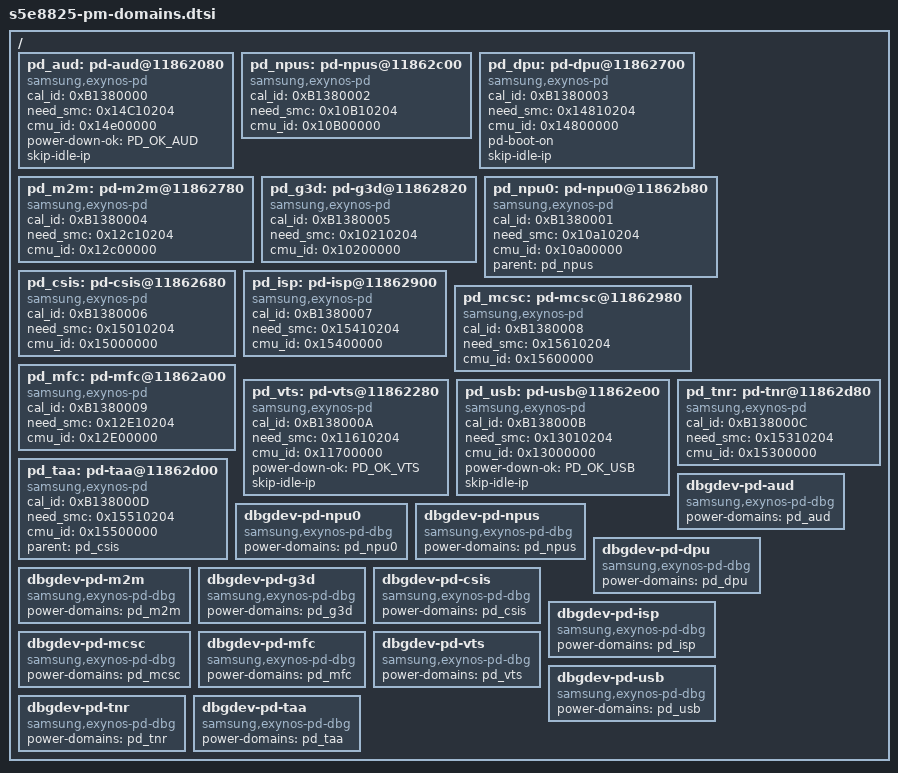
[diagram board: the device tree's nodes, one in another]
/*
 * SAMSUNG EXYNOS2100 SoC PM Domains device tree source
 *
 * Copyright (c) 2019 Samsung Electronics Co., Ltd.
 *		http://www.samsung.com
 *
 * SAMSUNG S5E8825 SoC PM domains device nodes are listed in this file.
 * EXYNOS9830 based board files can include this file and provide
 * values for board specfic bindings.
 *
 * This program is free software; you can redistribute it and/or modify
 * it under the terms of the GNU General Public License version 2 as
 * published by the Free Software Foundation.
 */
#include <dt-bindings/power/exynos-power.h>

/ {
	pd_aud: pd-aud@11862080 {
		compatible = "samsung,exynos-pd";
		cal_id = <0xB1380000>;
		need_smc = <0x14C10204>;
		cmu_id = <0x14e00000>;
		status = "okay";
		power-down-ok = <PD_OK_AUD>;
		#power-domain-cells = <0>;
		skip-idle-ip;
	};

	pd_npus: pd-npus@11862c00 {
		compatible = "samsung,exynos-pd";
		cal_id = <0xB1380002>;
		need_smc = <0x10B10204>;
		cmu_id = <0x10B00000>;
		status = "okay";
		#power-domain-cells = <0>;
	};

	pd_dpu: pd-dpu@11862700 {
		compatible = "samsung,exynos-pd";
		cal_id = <0xB1380003>;
		need_smc = <0x14810204>;
		cmu_id = <0x14800000>;
		status = "okay";
		#power-domain-cells = <0>;
		pd-boot-on;
		skip-idle-ip;
	};

	pd_m2m: pd-m2m@11862780 {
		compatible = "samsung,exynos-pd";
		cal_id = <0xB1380004>;
		need_smc = <0x12c10204>;
		cmu_id = <0x12c00000>;
		status = "okay";
		#power-domain-cells = <0>;
	};

	pd_g3d: pd-g3d@11862820 {
		compatible = "samsung,exynos-pd";
		cal_id = <0xB1380005>;
		need_smc = <0x10210204>;
		cmu_id = <0x10200000>;
		status = "okay";
		#power-domain-cells = <0>;
	};

	pd_npu0: pd-npu0@11862b80 {
		compatible = "samsung,exynos-pd";
		cal_id = <0xB1380001>;
		need_smc = <0x10a10204>;
		cmu_id = <0x10a00000>;
		status = "okay";
		parent = <&pd_npus>;
		#power-domain-cells = <0>;
	};

	pd_csis: pd-csis@11862680 {
		compatible = "samsung,exynos-pd";
		cal_id = <0xB1380006>;
		need_smc = <0x15010204>;
		cmu_id = <0x15000000>;
		status = "okay";
		#power-domain-cells = <0>;
	};

	pd_isp: pd-isp@11862900 {
		compatible = "samsung,exynos-pd";
		cal_id = <0xB1380007>;
		need_smc = <0x15410204>;
		cmu_id = <0x15400000>;
		status = "okay";
		#power-domain-cells = <0>;
	};

	pd_mcsc: pd-mcsc@11862980 {
		compatible = "samsung,exynos-pd";
		cal_id = <0xB1380008>;
		need_smc = <0x15610204>;
		cmu_id = <0x15600000>;
		status = "okay";
		#power-domain-cells = <0>;
	};

	pd_mfc: pd-mfc@11862a00 {
		compatible = "samsung,exynos-pd";
		cal_id = <0xB1380009>;
		need_smc = < 0x12E10204>;
		cmu_id = <0x12E00000>;
		status = "okay";
		#power-domain-cells = <0>;
	};

	pd_vts: pd-vts@11862280 {
		compatible = "samsung,exynos-pd";
		cal_id = <0xB138000A>;
		need_smc = <0x11610204>;
		cmu_id = <0x11700000>;
		status = "okay";
		power-down-ok = <PD_OK_VTS>;
		#power-domain-cells = <0>;
		skip-idle-ip;
	};

	pd_usb: pd-usb@11862e00 {
		compatible = "samsung,exynos-pd";
		cal_id = <0xB138000B>;
		need_smc = <0x13010204>;
		cmu_id = <0x13000000>;
		status = "okay";
		#power-domain-cells = <0>;
		power-down-ok = <PD_OK_USB>;
		skip-idle-ip;
	};

	pd_tnr: pd-tnr@11862d80 {
		compatible = "samsung,exynos-pd";
		cal_id = <0xB138000C>;
		need_smc = <0x15310204>;
		cmu_id = <0x15300000>;
		status = "okay";
		#power-domain-cells = <0>;
	};

	pd_taa: pd-taa@11862d00 {
		compatible = "samsung,exynos-pd";
		cal_id = <0xB138000D>;
		need_smc = <0x15510204>;
		cmu_id = <0x15500000>;
		status = "okay";
		parent = <&pd_csis>;
		#power-domain-cells = <0>;
	};

	dbgdev-pd-aud {
		compatible = "samsung,exynos-pd-dbg";
		power-domains = <&pd_aud>;
	};

	dbgdev-pd-npu0 {
		compatible = "samsung,exynos-pd-dbg";
		power-domains = <&pd_npu0>;
	};

	dbgdev-pd-npus {
		compatible = "samsung,exynos-pd-dbg";
		power-domains = <&pd_npus>;
	};

	dbgdev-pd-dpu {
		compatible = "samsung,exynos-pd-dbg";
		power-domains = <&pd_dpu>;
	};

	dbgdev-pd-m2m {
		compatible = "samsung,exynos-pd-dbg";
		power-domains = <&pd_m2m>;
	};

	dbgdev-pd-g3d {
		compatible = "samsung,exynos-pd-dbg";
		power-domains = <&pd_g3d>;
	};

	dbgdev-pd-csis {
		compatible = "samsung,exynos-pd-dbg";
		power-domains = <&pd_csis>;
	};

	dbgdev-pd-isp {
		compatible = "samsung,exynos-pd-dbg";
		power-domains = <&pd_isp>;
	};

	dbgdev-pd-mcsc {
		compatible = "samsung,exynos-pd-dbg";
		power-domains = <&pd_mcsc>;
	};

	dbgdev-pd-mfc {
		compatible = "samsung,exynos-pd-dbg";
		power-domains = <&pd_mfc>;
	};

	dbgdev-pd-vts {
		compatible = "samsung,exynos-pd-dbg";
		power-domains = <&pd_vts>;
	};

	dbgdev-pd-usb {
		compatible = "samsung,exynos-pd-dbg";
		power-domains = <&pd_usb>;
	};

	dbgdev-pd-tnr {
		compatible = "samsung,exynos-pd-dbg";
		power-domains = <&pd_tnr>;
	};

	dbgdev-pd-taa {
		compatible = "samsung,exynos-pd-dbg";
		power-domains = <&pd_taa>;
	};
};
